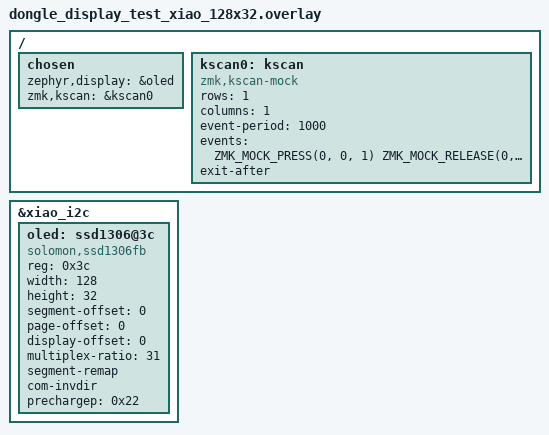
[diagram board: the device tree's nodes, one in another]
#include <dt-bindings/zmk/kscan_mock.h>

/ {
    chosen {
        zephyr,display = &oled;
        zmk,kscan = &kscan0;
    };

    kscan0: kscan {
        compatible = "zmk,kscan-mock";
        rows = <1>;
        columns = <1>;
        event-period = <1000>;
        events = <ZMK_MOCK_PRESS(0, 0, 1) ZMK_MOCK_RELEASE(0, 0, 1)>;
        exit-after;
    };
};

&xiao_i2c {
    status = "okay";

    oled: ssd1306@3c {
        compatible = "solomon,ssd1306fb";
        reg = <0x3c>;
        width = <128>;
        height = <32>;
        segment-offset = <0>;
        page-offset = <0>;
        display-offset = <0>;
        multiplex-ratio = <31>;
        segment-remap;
        com-invdir;
        prechargep = <0x22>;
    };
};
